# RA4M1 register map
Vendor: Renesas Electronics Corporation; Series: RA4; File version: 1.2
CPU: CM4 r0p1, little endian, MPU, FPU, VTOR, 4 interrupt priority bits
Registers are 8-bit, read-write, reset 0x0 unless marked. A register's access mark holds for its fields unless they carry their own. Offsets are from the block's base; [hi:lo] are bit positions; {n}, {i} and the like mark numbered series; 'fields as' and 'values as' point back to an identical list.

## ICU — Interrupt Controller
Base 0x40006000
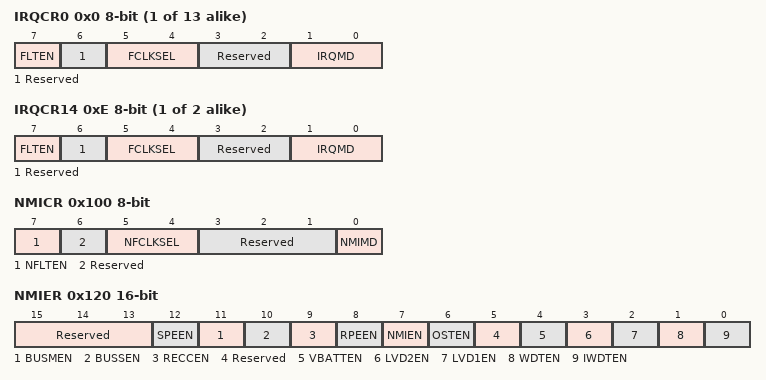
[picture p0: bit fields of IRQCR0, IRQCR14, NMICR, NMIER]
{0x0+i} IRQCR{i} (i=0..12) — IRQ Control Register {i}
  [7] FLTEN — IRQ Digital Filter Enable
    0=Digital filter disabled; 1=Digital filter enabled
  [6] Reserved — This bit is read as 0. The write value should be 0.
  [5:4] FCLKSEL — IRQ Digital Filter Sampling Clock Select
    0=PCLKB; 1=PCLKB/8; 2=PCLKB/32; 3=PCLKB/64
  [3:2] Reserved — These bits are read as 00. The write value should be 00.
  [1:0] IRQMD — IRQ Detection Sense Select
    0=Falling edge; 1=Rising edge; 2=Rising and falling edges; 3=Low level
{0x0+i} IRQCR{i} (i=14..15) — IRQ Control Register {i}
  fields as IRQCR0
0x100 NMICR — NMI Pin Interrupt Control Register
  [7] NFLTEN — NMI Digital Filter Enable
    0=Digital filter is disabled; 1=Digital filter is enabled
  [6] Reserved — This bit is read as 0. The write value should be 0.
  [5:4] NFCLKSEL — NMI Digital Filter Sampling Clock Select
    0=PCLKB; 1=PCLKB/8; 2=PCLKB/32; 3=PCLKB/64
  [3:1] Reserved — These bits are read as 000. The write value should be 000.
  [0] NMIMD — NMI Detection Set
    0=Falling edge; 1=Rising edge
0x120 NMIER 16-bit — Non-Maskable Interrupt Enable Register
  [15:13] Reserved — These bits are read as 000. The write value should be 000.
  [12] SPEEN — CPU Stack pointer monitor Interrupt Enable
    0=Disabled; 1=Enabled
  [11] BUSMEN — MPU Bus Master Error Interrupt Enable
    0=Disabled; 1=Enabled
  [10] BUSSEN — MPU Bus Slave Error Interrupt Enable
    0=Disabled; 1=Enabled
  [9] RECCEN — RAM ECC Error Interrupt Enable
    0=Disabled; 1=Enabled
  [8] RPEEN — RAM Parity Error Interrupt Enable
    0=Disabled; 1=Enabled
  [7] NMIEN — NMI Pin Interrupt Enable
    0=Disabled; 1=Enabled
  [6] OSTEN — Oscillation Stop Detection Interrupt Enable
    0=Disabled; 1=Enabled
  [5] Reserved — This bit is read as 0. The write value should be 0.
  [4] VBATTEN — VBATT monitor Interrupt Enable
    0=Disabled; 1=Enabled
  [3] LVD2EN — Voltage-Monitoring 2 Interrupt Enable
    0=Disabled; 1=Enabled
  [2] LVD1EN — Voltage-Monitoring 1 Interrupt Enable
    0=Disabled; 1=Enabled
  [1] WDTEN — WDT Underflow/Refresh Error Interrupt Enable
    0=Disabled; 1=Enabled
  [0] IWDTEN — IWDT Underflow/Refresh Error Interrupt Enable
    0=Disabled; 1=Enabled
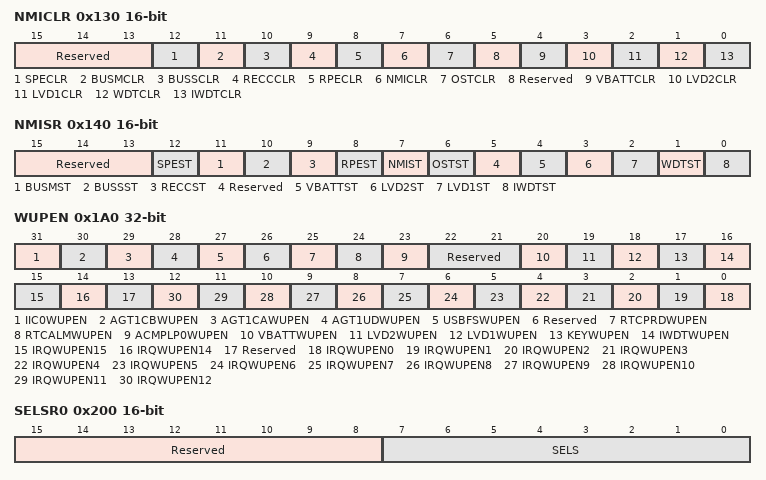
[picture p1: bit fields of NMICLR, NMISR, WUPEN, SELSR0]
0x130 NMICLR 16-bit — Non-Maskable Interrupt Status Clear Register
  [15:13] Reserved — These bits are read as 000. The write value should be 000.
  [12] SPECLR wo — CPU Stack Pointer Monitor Interrupt Clear
    0=No effect; 1=Clear the NMISR.SPEST flag
  [11] BUSMCLR wo — Bus Master Error Clear
    0=No effect; 1=Clear the NMISR.BUSMST flag
  [10] BUSSCLR wo — Bus Slave Error Clear
    0=No effect; 1=Clear the NMISR.BUSSST flag
  [9] RECCCLR wo — SRAM ECC Error Clear
    0=No effect; 1=Clear the NMISR.RECCST flag
  [8] RPECLR wo — SRAM Parity Error Clear
    0=No effect; 1=Clear the NMISR.RPEST flag
  [7] NMICLR wo — NMI Clear
    0=No effect; 1=Clear the NMISR.NMIST flag
  [6] OSTCLR wo — OST Clear
    0=No effect; 1=Clear the NMISR.OSTST flag
  [5] Reserved — This bit is read as 0. The write value should be 0.
  [4] VBATTCLR wo — VBATT Clear
    0=No effect; 1=Clear the NMISR.VBATTST flag
  [3] LVD2CLR wo — LVD2 Clear
    0=No effect; 1=Clear the NMISR.LVD2ST flag
  [2] LVD1CLR wo — LVD1 Clear
    0=No effect; 1=Clear the NMISR.LVD1ST flag
  [1] WDTCLR wo — WDT Clear
    0=No effect; 1=Clear the NMISR.WDTST flag
  [0] IWDTCLR wo — IWDT Clear
    0=No effect; 1=Clear the NMISR.IWDTST flag
0x140 NMISR 16-bit ro — Non-Maskable Interrupt Status Register
  [15:13] Reserved — These bits are read as 000.
  [12] SPEST — CPU Stack pointer monitor Interrupt Status Flag
    0=Interrupt not requested; 1=Interrupt requested
  [11] BUSMST — MPU Bus Master Error Interrupt Status Flag
    0=Interrupt not requested; 1=Interrupt requested
  [10] BUSSST — MPU Bus Slave Error Interrupt Status Flag
    0=Interrupt not requested; 1=Interrupt requested
  [9] RECCST — RAM ECC Error Interrupt Status Flag
    0=Interrupt not requested; 1=Interrupt requested
  [8] RPEST — RAM Parity Error Interrupt Status Flag
    0=Interrupt not requested; 1=Interrupt requested
  [7] NMIST — NMI Status Flag
    0=Interrupt not requested; 1=Interrupt requested
  [6] OSTST — Oscillation Stop Detection Interrupt Status Flag
    0=Interrupt not requested for main oscillation stop; 1=Interrupt requested for main oscillation stop
  [5] Reserved — This bit is read as 0.
  [4] VBATTST — VBATT monitor Interrupt Status Flag
    0=Interrupt not requested; 1=Interrupt requested
  [3] LVD2ST — Voltage-Monitoring 2 Interrupt Status Flag
    0=Interrupt not requested; 1=Interrupt requested
  [2] LVD1ST — Voltage-Monitoring 1 Interrupt Status Flag
    0=Interrupt not requested; 1=Interrupt requested
  [1] WDTST — WDT Underflow/Refresh Error Status Flag
    0=Interrupt not requested; 1=Interrupt requested
  [0] IWDTST — IWDT Underflow/Refresh Error Status Flag
    0=Interrupt not requested; 1=Interrupt requested
0x1A0 WUPEN 32-bit — Wake Up Interrupt Enable Register
  [31] IIC0WUPEN — IIC0 address match interrupt S/W standby returns enable
    0=S/W standby returns by IIC0 address match interrupt is disabled; 1=S/W standby returns by IIC0 address match interrupt is enabled
  [30] AGT1CBWUPEN — AGT1 compare match B interrupt S/W standby returns enable
    0=S/W standby returns by AGT1 compare match B interrupt is disabled; 1=S/W standby returns by AGT1 compare match B interrupt is enabled
  [29] AGT1CAWUPEN — AGT1 compare match A interrupt S/W standby returns enable
    0=S/W standby returns by AGT1 compare match A interrupt is disabled; 1=S/W standby returns by AGT1 compare match A interrupt is enabled
  [28] AGT1UDWUPEN — AGT1 underflow interrupt S/W standby returns enable
    0=S/W standby returns by AGT1 underflow interrupt is disabled; 1=S/W standby returns by AGT1 underflow interrupt is enabled
  [27] USBFSWUPEN — USBFS interrupt S/W standby returns enable
    0=S/W standby returns by USBFS interrupt is disabled; 1=S/W standby returns by USBFS interrupt is enabled
  [26] Reserved — This bit is read as 0. The write value should be 0.
  [25] RTCPRDWUPEN — RCT period interrupt S/W standby returns enable
    0=S/W standby returns by RTC period interrupt is disabled; 1=S/W standby returns by RTC period interrupt is enabled
  [24] RTCALMWUPEN — RTC alarm interrupt S/W standby returns enable
    0=S/W standby returns by RTC alarm interrupt is disabled; 1=S/W standby returns by RTC alarm interrupt is enabled
  [23] ACMPLP0WUPEN — ACMPLP0 interrupt S/W standby returns enable
    0=S/W standby returns by ACMPLP0 interrupt is disabled; 1=S/W standby returns by ACMPLP0 interrupt is enabled
  [22:21] Reserved — These bits are read as 00. The write value should be 00.
  [20] VBATTWUPEN — VBATT monitor interrupt S/W standby returns enable
    0=S/W standby returns by VBATT monitor interrupt is disabled; 1=S/W standby returns by VBATT monitor interrupt is enabled
  [19] LVD2WUPEN — LVD2 interrupt S/W standby returns enable
    0=S/W standby returns by LVD2 interrupt is disabled; 1=S/W standby returns by LVD2 interrupt is enabled
  [18] LVD1WUPEN — LVD1 interrupt S/W standby returns enable
    0=S/W standby returns by LVD1 interrupt is disabled; 1=S/W standby returns by LVD1 interrupt is enabled
  [17] KEYWUPEN — Key interrupt S/W standby returns enable
    0=S/W standby returns by KEY interrupt is disabled; 1=S/W standby returns by KEY interrupt is enabled
  [16] IWDTWUPEN — IWDT interrupt S/W standby returns enable
    0=S/W standby returns by IWDT interrupt is disabled; 1=S/W standby returns by IWDT interrupt is enabled
  [15] IRQWUPEN15 — IRQ15 interrupt S/W standby returns enable
    0=S/W standby returns by IRQ15 interrupt is disabled; 1=S/W standby returns by IRQ15 interrupt is enabled
  [14] IRQWUPEN14 — IRQ14 interrupt S/W standby returns enable
    0=S/W standby returns by IRQ14 interrupt is disabled; 1=S/W standby returns by IRQ14 interrupt is enabled
  [13] Reserved — This bit is read as 0. The write value should be 0.
  [n] IRQWUPEN{n} (n=0..12) — IRQ{n} interrupt S/W standby returns enable
    0=S/W standby returns by IRQ{n} interrupt is disabled; 1=S/W standby returns by IRQ{n} interrupt is enabled
0x200 SELSR0 16-bit — SYS Event Link Setting Register
  [15:8] Reserved — These bits are read as 00000000. The write value should be 00000000.
  [7:0] SELS — SYS Event Link Select
    0=Disable event output to the associated low-power mode module; other=others (Event signal number to be linked)
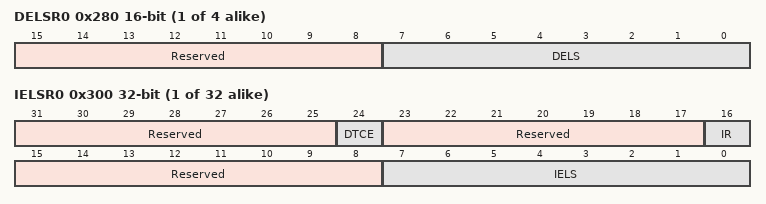
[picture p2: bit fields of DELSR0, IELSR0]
{0x280+4i} DELSR{i} (i=0..3) 16-bit — DMAC Event Link Setting Register {i}
  [15:8] Reserved — These bits are read as 00000000. The write value should be 00000000.
  [7:0] DELS — Event selection to DMAC Start request
    0=Nothing is selected; other=others (See Event Table)
{0x300+4i} IELSR{i} (i=0..31) 32-bit — ICU Event Link Setting Register {i}
  [31:25] Reserved — These bits are read as 0000000. The write value should be 0000000.
  [24] DTCE — DTC Activation Enable
    0=DTC activation is disabled; 1=DTC activation is enabled
  [23:17] Reserved — These bits are read as 0000000. The write value should be 0000000.
  [16] IR — Interrupt Status Flag
    0=No interrupt request is generated; 1=An interrupt request is generated ( 1 write to the IR bit is prohibited. )
  [15:8] Reserved — These bits are read as 00000000. The write value should be 00000000.
  [7:0] IELS — ICU Event selection to NVIC Set the number for the event signal to be linked .
    0=Nothing is selected; other=others (See Event Table)
